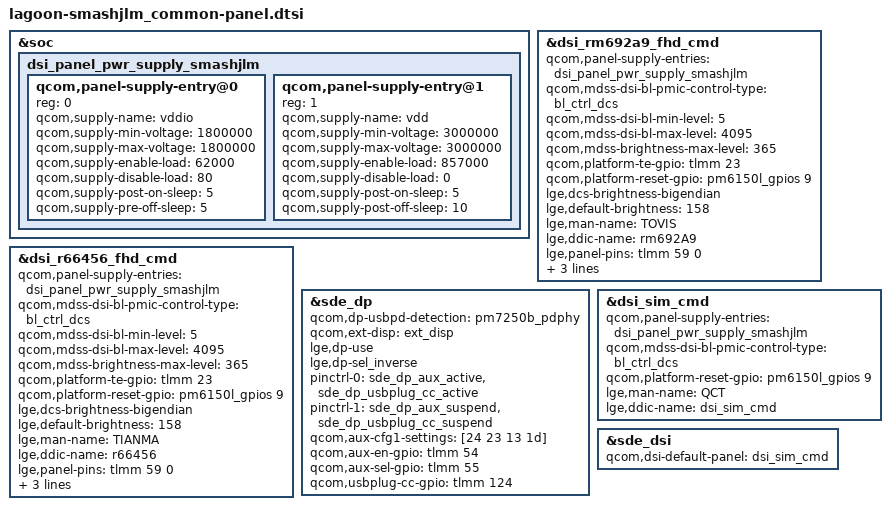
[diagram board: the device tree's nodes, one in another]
// SPDX-License-Identifier: GPL-2.0-only
/*
 * Copyright (c) 2018-2019, The Linux Foundation. All rights reserved.
 */

#include "dsi-panel-rm692a9-tovis-fhd-cmd.dtsi"
#include "dsi-panel-r66456-tianma-fhd-cmd.dtsi"

&soc {
	dsi_panel_pwr_supply_smashjlm: dsi_panel_pwr_supply_smashjlm {
		#address-cells = <1>;
		#size-cells = <0>;

		qcom,panel-supply-entry@0 {
			reg = <0>;
			qcom,supply-name = "vddio";
			qcom,supply-min-voltage = <1800000>;
			qcom,supply-max-voltage = <1800000>;
			qcom,supply-enable-load = <62000>;
			qcom,supply-disable-load = <80>;
			qcom,supply-post-on-sleep = <5>;
			qcom,supply-pre-off-sleep = <5>;
		};

		qcom,panel-supply-entry@1 {
			reg = <1>;
			qcom,supply-name = "vdd";
			qcom,supply-min-voltage = <3000000>;
			qcom,supply-max-voltage = <3000000>;
			qcom,supply-enable-load = <857000>;
			qcom,supply-disable-load = <0>;
			qcom,supply-post-on-sleep = <5>;
			qcom,supply-post-off-sleep = <10>;
		};
	};
};

&dsi_rm692a9_fhd_cmd {
	qcom,panel-supply-entries = <&dsi_panel_pwr_supply_smashjlm>;
	qcom,mdss-dsi-bl-pmic-control-type = "bl_ctrl_dcs";
	qcom,mdss-dsi-bl-min-level = <5>;
	qcom,mdss-dsi-bl-max-level = <4095>;
	qcom,mdss-brightness-max-level = <365>;
	qcom,platform-te-gpio = <&tlmm 23 0>;
	qcom,platform-reset-gpio = <&pm6150l_gpios 9 0>;
	lge,dcs-brightness-bigendian;
	lge,default-brightness = <158>;
	lge,man-name = "TOVIS";
	lge,ddic-name = "rm692A9";
	lge,panel-pins =<&tlmm 59 0>; // dsv_en
	lge,panel-on-pin-seq = <0 1 0>;
	lge,panel-off-pin-seq = <0 0 10>;
	lge,use-labibb;
};

&dsi_r66456_fhd_cmd {
	qcom,panel-supply-entries = <&dsi_panel_pwr_supply_smashjlm>;
	qcom,mdss-dsi-bl-pmic-control-type = "bl_ctrl_dcs";
	qcom,mdss-dsi-bl-min-level = <5>;
	qcom,mdss-dsi-bl-max-level = <4095>;
	qcom,mdss-brightness-max-level = <365>;
	qcom,platform-te-gpio = <&tlmm 23 0>;
	qcom,platform-reset-gpio = <&pm6150l_gpios 9 0>;
	lge,dcs-brightness-bigendian;
	lge,default-brightness = <158>;
	lge,man-name = "TIANMA";
	lge,ddic-name = "r66456";
	lge,panel-pins =<&tlmm 59 0>; // dsv_en
	lge,panel-on-pin-seq = <0 1 0>;
	lge,panel-off-pin-seq = <0 0 10>;
	lge,use-labibb;
};

&sde_dp {
	qcom,dp-usbpd-detection = <&pm7250b_pdphy>;
	qcom,ext-disp = <&ext_disp>;
	lge,dp-use;
	lge,dp-sel_inverse;
	pinctrl-names = "mdss_dp_active", "mdss_dp_sleep", "default";
	pinctrl-0 = <&sde_dp_aux_active &sde_dp_usbplug_cc_active>;
	pinctrl-1 = <&sde_dp_aux_suspend &sde_dp_usbplug_cc_suspend>;

	qcom,aux-cfg1-settings = [24 23 13 1d];
	qcom,aux-en-gpio = <&tlmm 54 0>;
	qcom,aux-sel-gpio = <&tlmm 55 0>;
	qcom,usbplug-cc-gpio = <&tlmm 124 0>;
};

&dsi_sim_cmd {
    qcom,panel-supply-entries = <&dsi_panel_pwr_supply_smashjlm>;
    qcom,mdss-dsi-bl-pmic-control-type = "bl_ctrl_dcs";
	qcom,platform-reset-gpio = <&pm6150l_gpios 9 0>;
    lge,man-name = "QCT";
    lge,ddic-name = "dsi_sim_cmd";
};

&sde_dsi {
	qcom,dsi-default-panel = <&dsi_sim_cmd>;
};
